# ATSAMG55G19 register map
Vendor: Atmel; Series: SAMG55; File version: 0
CPU: CM4 r0p1, selectable endian, MPU, FPU, 4 interrupt priority bits
Registers are 32-bit, read-write, reset 0x0 unless marked. A register's access mark holds for its fields unless they carry their own. Offsets are from the block's base; [hi:lo] are bit positions; {n}, {i} and the like mark numbered series.

## MATRIX — AHB Bus Matrix
Base 0x400E0200
{0x0+4i} MATRIX_MCFG[{i}] (i=0..2) reset not defined — Master Configuration Register
  [2:0] ULBT — Undefined Length Burst Type
    0=INFINITE (No predicted end of burst is generated and therefore INCR bursts coming from this master cannot be broken.); 1=SINGLE (The undefined length burst is treated as a succession of single access allowing rearbitration at each beat of the INCR burst.); 2=FOUR_BEAT (The undefined length burst is split into a 4-beat bursts allowing rearbitration at each 4-beat burst end.); 3=EIGHT_BEAT (The undefined length burst is split into 8-beat bursts allowing rearbitration at each 8-beat burst end.); 4=SIXTEEN_BEAT (The undefined length burst is split into 16-beat bursts allowing rearbitration at each 16-beat burst end.)
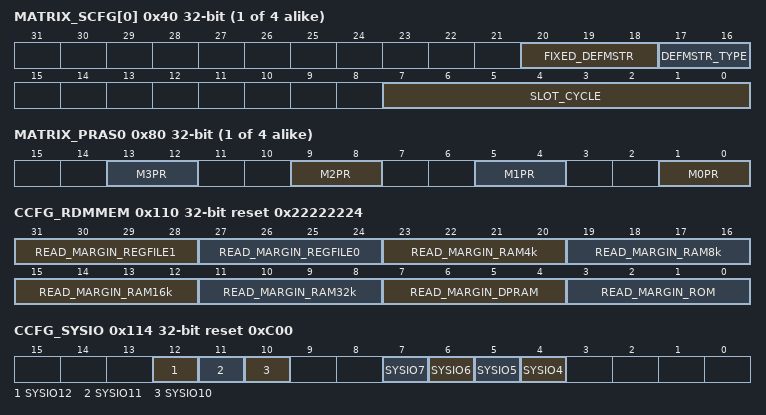
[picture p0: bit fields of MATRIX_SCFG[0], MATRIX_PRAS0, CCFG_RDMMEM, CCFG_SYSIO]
{0x40+4i} MATRIX_SCFG[{i}] (i=0..3) reset not defined — Slave Configuration Register
  [20:18] FIXED_DEFMSTR — Fixed Default Master
  [17:16] DEFMSTR_TYPE — Default Master Type
    0=NO_DEFAULT (At the end of current slave access, if no other master request is pending, the slave is disconnected from all masters.This results in having a one cycle latency for the first access of a burst transfer or for a single access.); 1=LAST (At the end of current slave access, if no other master request is pending, the slave stays connected to the last master having accessed it.This results in not having the one cycle latency when the last master tries to access the slave again.); 2=FIXED (At the end of the current slave access, if no other master request is pending, the slave connects to the fixed master the number that has been written in the FIXED_DEFMSTR field.This results in not having the one cycle latency when the fixed master tries to access the slave again.)
  [7:0] SLOT_CYCLE — Maximum Number of Allowed Cycles for a Burst
{0x80+8i} MATRIX_PRAS{i} (i=0..3) — Priority Register A for Slave {i}
  [4n+1:4n] M{n}PR (n=0..3) — Master {n} Priority
0x110 CCFG_RDMMEM reset 0x22222224 — Embedded Memories Read Margin Values Register
  [31:28] READ_MARGIN_REGFILE1 — REGFILE1 Read Margin Value Selection
  [27:24] READ_MARGIN_REGFILE0 — REGFILE0 Read Margin Value Selection
  [23:20] READ_MARGIN_RAM4k — RAM4k Read Margin Value Selection
  [19:16] READ_MARGIN_RAM8k — RAM8k Read Margin Value Selection
  [15:12] READ_MARGIN_RAM16k — RAM16k Read Margin Value Selection
  [11:8] READ_MARGIN_RAM32k — RAM32k Read Margin Value Selection
  [7:4] READ_MARGIN_DPRAM — DPRAM Read Margin Value Selection
  [3:0] READ_MARGIN_ROM — ROM Read Margin Value Selection
0x114 CCFG_SYSIO reset 0xC00 — System I/O Configuration Register
  [12] SYSIO12 — PB12 or ERASE Assignment
  [11] SYSIO11
  [10] SYSIO10 — PA21 or DM Assignment
  [7] SYSIO7 — PB7 or TCK/SWCLK Assignment
  [6] SYSIO6 — PB6 or TMS/SWDIO Assignment
  [5] SYSIO5 — PB5 or TDO/TRACESWO Assignment
  [4] SYSIO4 — PB4 or TDI Assignment
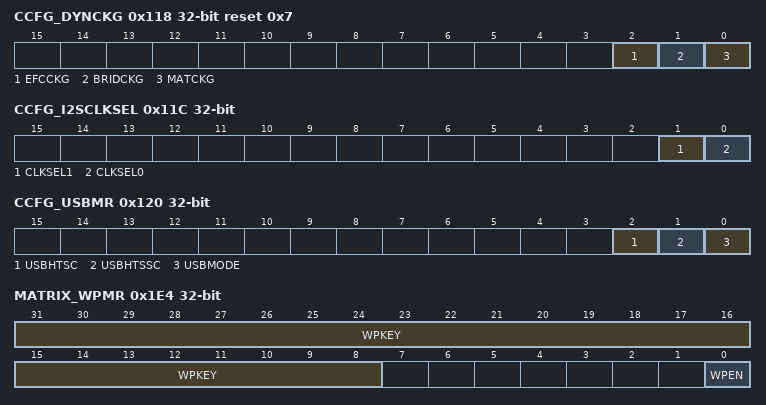
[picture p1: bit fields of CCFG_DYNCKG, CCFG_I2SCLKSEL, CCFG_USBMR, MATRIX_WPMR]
0x118 CCFG_DYNCKG reset 0x7 — Dynamic Clock Gating Register
  [2] EFCCKG — EFC Dynamic Clock Gating Enable
  [1] BRIDCKG — Bridge Dynamic Clock Gating Enable
  [0] MATCKG — MATRIX Dynamic Clock Gating
0x11C CCFG_I2SCLKSEL — I2S Clock Source Selection Register
  [1] CLKSEL1 — I2S1 clock source
  [0] CLKSEL0 — I2S0 clock source
0x120 CCFG_USBMR — USB Management Register
  [2] USBHTSC — USB Host Transceiver Suspend Control
  [1] USBHTSSC — USB Transceiver Suspend Software Control
  [0] USBMODE — USB mode selection
0x1E4 MATRIX_WPMR — Write Protection Mode Register
  [31:8] WPKEY — Write Protection Key
    0x4D4154=PASSWD (Writing any other value in this field aborts the write operation of the WPEN bit. Always reads as 0.)
  [0] WPEN — Write Protection Enable
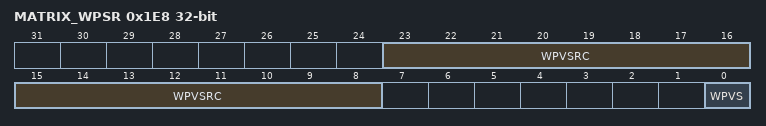
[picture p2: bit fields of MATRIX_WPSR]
0x1E8 MATRIX_WPSR ro — Write Protection Status Register
  [23:8] WPVSRC — Write Protection Violation Source
  [0] WPVS — Write Protection Violation Status
